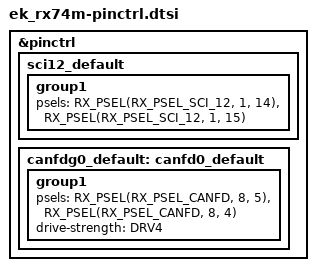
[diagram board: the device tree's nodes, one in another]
/*
 * Copyright (c) 2026 Renesas Electronics Corporation
 * SPDX-License-Identifier: Apache-2.0
 */

&pinctrl {
	sci12_default: sci12_default {
		group1 {
			psels = <RX_PSEL(RX_PSEL_SCI_12, 1, 14)>, /* TX */
				<RX_PSEL(RX_PSEL_SCI_12, 1, 15)>; /* RX */
		};
	};

	canfdg0_default: canfd0_default {
		group1 {
			/* CRX0 CTX0 */
			psels = <RX_PSEL(RX_PSEL_CANFD, 8, 5)>,
				<RX_PSEL(RX_PSEL_CANFD, 8, 4)>;
			drive-strength = "DRV4";
		};
	};
};
